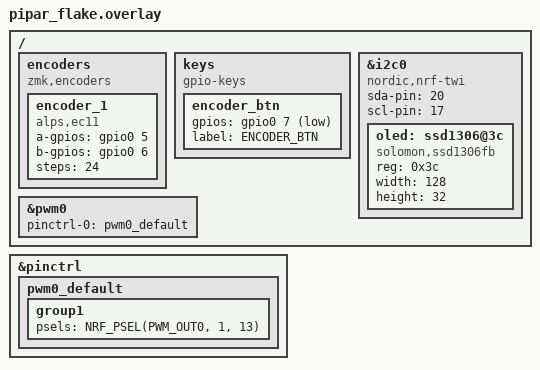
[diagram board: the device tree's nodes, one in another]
/*
 * Cấu hình phần cứng cho Pipar Flake
 * Encoder + OLED + GPIO
 */

/ {
    /* 1. Encoder - Phải dùng chuẩn ZMK */
    encoders {
        compatible = "zmk,encoders";
        encoder_1: encoder_1 {
            compatible = "alps,ec11";
            a-gpios = <&gpio0 5 (GPIO_ACTIVE_HIGH | GPIO_PULL_UP)>;
            b-gpios = <&gpio0 6 (GPIO_ACTIVE_HIGH | GPIO_PULL_UP)>;
            steps = <24>;
        };
    };

    /* 2. Nút nhấn encoder */
    keys {
        compatible = "gpio-keys";
        encoder_btn: encoder_btn {
            gpios = <&gpio0 7 (GPIO_ACTIVE_LOW | GPIO_PULL_UP)>;
            label = "ENCODER_BTN";
        };
    };

    /* 3. I2C cho OLED */
    &i2c0 {
        compatible = "nordic,nrf-twi";
        status = "okay";
        sda-pin = <20>;
        scl-pin = <17>;

        oled: ssd1306@3c {
            compatible = "solomon,ssd1306fb";
            reg = <0x3c>;
            width = <128>;
            height = <32>;
        };
    };

    /* 4. PWM Backlight */
    &pwm0 {
        status = "okay";
        pinctrl-0 = <&pwm0_default>;
        pinctrl-names = "default";
    };
};

/* Riêng pinctrl phải đặt ngoài root node */
&pinctrl {
    pwm0_default: pwm0_default {
        group1 {
            psels = <NRF_PSEL(PWM_OUT0, 1, 13)>;
        };
    };
};
